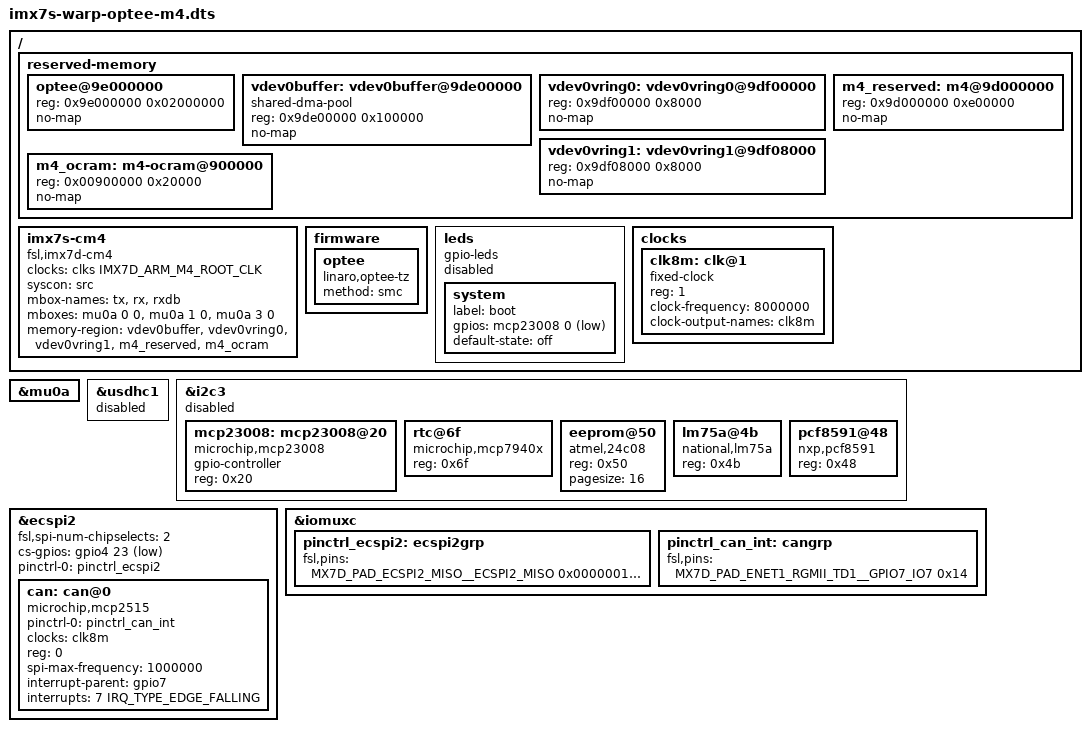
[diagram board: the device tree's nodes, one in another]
// SPDX-License-Identifier: (GPL-2.0+ OR MIT)
/*
 * WaRP7 with the IO board: upstream imx7s-warp.dts plus the OP-TEE nodes, the
 * IO board devices and the Cortex-M4 (remoteproc, RPMsg). The I2C devices
 * belong to OP-TEE.
 */

#include "imx7s-warp.dts"

/ {
	/*
	 * OP-TEE is loaded by TF-A BL2 in the last 32 MiB of DDR
	 * (TZDRAM 0x9e000000 + shared memory 0x9fe00000).
	 */
	reserved-memory {
		#address-cells = <1>;
		#size-cells = <1>;
		ranges;

		optee@9e000000 {
			reg = <0x9e000000 0x02000000>;
			no-map;
		};

		/*
		 * Cortex-M4, just below OP-TEE: RPMsg buffers and vrings (their
		 * addresses are built into the M4 firmware), then 14 MiB for
		 * firmware linked to run from DDR (M4 code alias 0x1d000000).
		 */
		vdev0buffer: vdev0buffer@9de00000 {
			compatible = "shared-dma-pool";
			reg = <0x9de00000 0x100000>;
			no-map;
		};

		vdev0vring0: vdev0vring0@9df00000 {
			reg = <0x9df00000 0x8000>;
			no-map;
		};

		vdev0vring1: vdev0vring1@9df08000 {
			reg = <0x9df08000 0x8000>;
			no-map;
		};

		m4_reserved: m4@9d000000 {
			reg = <0x9d000000 0xe00000>;
			no-map;
		};

		/* OCRAM (128 KiB): M4 code, e.g. Zephyr with zephyr,flash = &ocram_code */
		m4_ocram: m4-ocram@900000 {
			reg = <0x00900000 0x20000>;
			no-map;
		};
	};

	/*
	 * Started by Linux from /lib/firmware (remoteproc). Its boot vector goes
	 * to OCRAM_S, which OP-TEE must leave open (CFG_IMX_CSU_M4_OCRAM_S=y).
	 */
	imx7s-cm4 {
		compatible = "fsl,imx7d-cm4";
		clocks = <&clks IMX7D_ARM_M4_ROOT_CLK>;
		syscon = <&src>;
		mbox-names = "tx", "rx", "rxdb";
		/* MU channel 0: the M4 kicks with MU register id = vring id */
		mboxes = <&mu0a 0 0>, <&mu0a 1 0>, <&mu0a 3 0>;
		/*
		 * vdev0buffer first: the RPMsg buffer pool is region 0. The others
		 * are where imx_rproc may load firmware, besides OCRAM_S and the TCM.
		 */
		memory-region = <&vdev0buffer>, <&vdev0vring0>, <&vdev0vring1>,
				<&m4_reserved>, <&m4_ocram>;
	};

	firmware {
		optee {
			compatible = "linaro,optee-tz";
			method = "smc";
		};
	};

	leds {
		compatible = "gpio-leds";
		/* mcp23008 is on i2c3, owned by OP-TEE */
		status = "disabled";

		system {
			label = "boot";
			gpios = <&mcp23008 0 GPIO_ACTIVE_LOW>;
			default-state = "off";
		};
	};

	clocks {
		#address-cells = <1>;
		#size-cells = <0>;

		/* fixed crystal dedicated to the mcp251x */
		clk8m: clk@1 {
			compatible = "fixed-clock";
			reg = <1>;
			#clock-cells = <0>;
			clock-frequency = <8000000>;
			clock-output-names = "clk8m";
		};
	};
};

/* Linux side of the MU, the RPMsg doorbell with the Cortex-M4 */
&mu0a {
	status = "okay";
};

/*
 * Wi-Fi (BCM43430) disabled: its power-up when brcmfmac loads resets the
 * board. Keeping usdhc1 off leaves reg_brcm, the chip supply, off.
 */
&usdhc1 {
	status = "disabled";
};

/*
 * IO board I2C bus: owned by OP-TEE (imx7s-warp-optee.dts in OP-TEE), the
 * devices are reached through the i2c_devices PTA and /dev/rtc via rtc-optee.
 */
&i2c3 {
	status = "disabled";

	mcp23008: mcp23008@20 {
		compatible = "microchip,mcp23008";
		gpio-controller;
		#gpio-cells = <2>;
		reg = <0x20>;
	};

	rtc@6f {
		compatible = "microchip,mcp7940x";
		reg = <0x6f>;
	};

	eeprom@50 {
		compatible = "atmel,24c08";
		reg = <0x50>;
		pagesize = <16>;
	};

	lm75a@4b {
		compatible = "national,lm75a";
		reg = <0x4b>;
	};

	pcf8591@48 {
		compatible = "nxp,pcf8591";
		reg = <0x48>;
	};
};

&ecspi2 {
	fsl,spi-num-chipselects = <2>;
	cs-gpios = <&gpio4 23 GPIO_ACTIVE_LOW>;
	pinctrl-names = "default";
	pinctrl-0 = <&pinctrl_ecspi2>;
	status = "okay";

	can: can@0 {
		compatible = "microchip,mcp2515";
		pinctrl-names = "can";
		pinctrl-0 = <&pinctrl_can_int>;
		clocks = <&clk8m>;
		reg = <0>;
		spi-max-frequency = <1000000>;
		interrupt-parent = <&gpio7>;
		interrupts = <7 IRQ_TYPE_EDGE_FALLING>;
	};
};

&iomuxc {
	pinctrl_ecspi2: ecspi2grp {
		fsl,pins = <
			MX7D_PAD_ECSPI2_MISO__ECSPI2_MISO	0x00000014
			MX7D_PAD_ECSPI2_MOSI__ECSPI2_MOSI	0x00000014
			MX7D_PAD_ECSPI2_SCLK__ECSPI2_SCLK	0x00000014
			MX7D_PAD_ECSPI2_SS0__ECSPI2_SS0		0x00000014
		>;
	};

	pinctrl_can_int: cangrp {
		fsl,pins = <
			MX7D_PAD_ENET1_RGMII_TD1__GPIO7_IO7	0x14 /* INT */
		>;
	};
};
